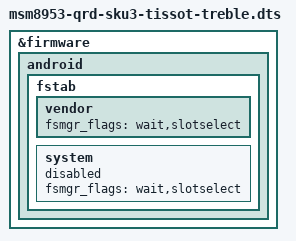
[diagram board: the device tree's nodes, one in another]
/*
 * Treble (system-as-root / vendor-only) variant of tissot.
 * Includes the stock tissot board, then activates the vendor fstab entry
 * (wait,slotselect) while leaving system disabled, matching the
 * proven A-only non-AB GSI-style layout.
 */
/dts-v1/;

#include "msm8953-qrd-sku3-tissot.dts"

&firmware {
	android {
		fstab {
			vendor {
				fsmgr_flags = "wait,slotselect";
				status = "ok";
			};
			system {
				fsmgr_flags = "wait,slotselect";
				status = "disable";
			};
		};
	};
};
